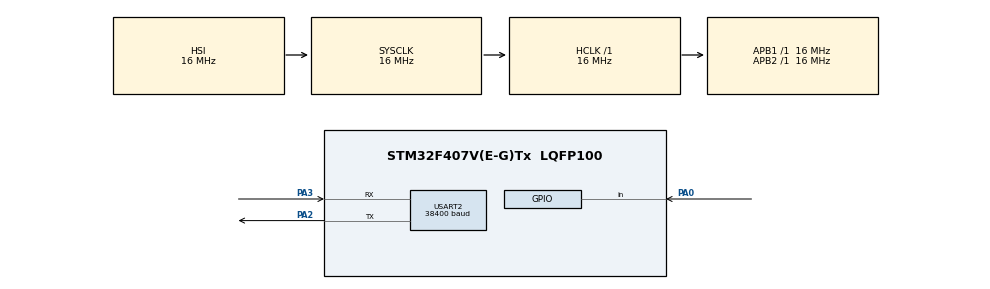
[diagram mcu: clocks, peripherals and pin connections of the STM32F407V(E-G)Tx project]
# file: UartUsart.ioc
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Mcu.Family=STM32F4
RCC.VCOOutputFreq_Value=192000000
RCC.APB2Freq_Value=16000000
RCC.CortexFreq_Value=16000000
Mcu.Name=STM32F407V(E-G)Tx
PA2.Signal=USART2_TX
RCC.SYSCLKFreq_VALUE=16000000
USART2.BaudRate=38400
Mcu.Package=LQFP100
ProjectManager.StackSize=0x400
PA0-WKUP.Signal=GPIO_Input
USART2.VirtualMode=VM_ASYNC
PA3.Mode=Asynchronous
ProjectManager.HeapSize=0x200
ProjectManager.TargetToolchain=STM32CubeIDE
RCC.HSI_VALUE=16000000
NVIC.PriorityGroup=NVIC_PRIORITYGROUP_4
PA2.Mode=Asynchronous
RCC.APB1Freq_Value=16000000
RCC.LSE_VALUE=32768
RCC.AHBFreq_Value=16000000
RCC.HSE_VALUE=25000000
PA3.Signal=USART2_RX
board=custom

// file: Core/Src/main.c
/* USER CODE BEGIN Header */
/**
  * main.c
  */
/* USER CODE END Header */
#include "main.h"

/* USER CODE BEGIN Includes */
#include <stdio.h>
#include "retarget.h"
/* USER CODE END Includes */

UART_HandleTypeDef huart2;

void SystemClock_Config(void);
static void MX_GPIO_Init(void);
static void MX_USART2_UART_Init(void);

int main(void)
{
  /* USER CODE BEGIN 1 */
  char buf[100];
  /* USER CODE END 1 */

  /* MCU Configuration--------------------------------------------------------*/

  /* Reset of all peripherals, Initializes the Flash interface and the Systick. */
  HAL_Init();

  /* Configure the system clock */
  SystemClock_Config();

  /* Initialize all configured peripherals */
  MX_GPIO_Init();
  MX_USART2_UART_Init();
  /* USER CODE BEGIN 2 */
  RetargetInit(&huart2);
  /* USER CODE END 2 */

  /* Infinite loop */
  /* USER CODE BEGIN WHILE */
  while (1)
  {
    printf("\r\nInserisci il tuo nome e premi INVIO: ");
    scanf("%s", buf);
    printf("\r\nBenvenuto, %s!\r\n", buf);
    /* USER CODE END WHILE */

  }
}

void SystemClock_Config(void)
{
  RCC_OscInitTypeDef RCC_OscInitStruct = {0};
  RCC_ClkInitTypeDef RCC_ClkInitStruct = {0};

  /** Configure the main internal regulator output voltage
  */
  __HAL_RCC_PWR_CLK_ENABLE();
  __HAL_PWR_VOLTAGESCALING_CONFIG(PWR_REGULATOR_VOLTAGE_SCALE1);
  /** Initializes the RCC Oscillators according to the specified parameters
  * in the RCC_OscInitTypeDef structure.
  */
  RCC_OscInitStruct.OscillatorType = RCC_OSCILLATORTYPE_HSI;
  RCC_OscInitStruct.HSIState = RCC_HSI_ON;
  RCC_OscInitStruct.HSICalibrationValue = RCC_HSICALIBRATION_DEFAULT;
  RCC_OscInitStruct.PLL.PLLState = RCC_PLL_NONE;
  if (HAL_RCC_OscConfig(&RCC_OscInitStruct) != HAL_OK)
  {
    Error_Handler();
  }
  /** Initializes the CPU, AHB and APB buses clocks
  */
  RCC_ClkInitStruct.ClockType = RCC_CLOCKTYPE_HCLK|RCC_CLOCKTYPE_SYSCLK
                              |RCC_CLOCKTYPE_PCLK1|RCC_CLOCKTYPE_PCLK2;
  RCC_ClkInitStruct.SYSCLKSource = RCC_SYSCLKSOURCE_HSI;
  RCC_ClkInitStruct.AHBCLKDivider = RCC_SYSCLK_DIV1;
  RCC_ClkInitStruct.APB1CLKDivider = RCC_HCLK_DIV1;
  RCC_ClkInitStruct.APB2CLKDivider = RCC_HCLK_DIV1;

  if (HAL_RCC_ClockConfig(&RCC_ClkInitStruct, FLASH_LATENCY_0) != HAL_OK)
  {
    Error_Handler();
  }
}

static void MX_USART2_UART_Init(void)
{

  huart2.Instance = USART2;
  huart2.Init.BaudRate = 38400;
  huart2.Init.WordLength = UART_WORDLENGTH_8B;
  huart2.Init.StopBits = UART_STOPBITS_1;
  huart2.Init.Parity = UART_PARITY_NONE;
  huart2.Init.Mode = UART_MODE_TX_RX;
  huart2.Init.HwFlowCtl = UART_HWCONTROL_NONE;
  huart2.Init.OverSampling = UART_OVERSAMPLING_16;
  if (HAL_UART_Init(&huart2) != HAL_OK)
  {
    Error_Handler();
  }

}

static void MX_GPIO_Init(void)
{
  GPIO_InitTypeDef GPIO_InitStruct = {0};

  /* GPIO Ports Clock Enable */
  __HAL_RCC_GPIOA_CLK_ENABLE();

  /*Configure GPIO pin : PA0 */
  GPIO_InitStruct.Pin = GPIO_PIN_0;
  GPIO_InitStruct.Mode = GPIO_MODE_INPUT;
  GPIO_InitStruct.Pull = GPIO_NOPULL;
  HAL_GPIO_Init(GPIOA, &GPIO_InitStruct);

}

void Error_Handler(void)
{
  __disable_irq();
  while (1)
  {
  }
}
